# R7FA8M1AH register map
Vendor: Renesas; Series: RA8; File version: 1.2
CPU: CM85 r0p0, little endian, MPU, FPU, VTOR, 4 interrupt priority bits
Registers are 32-bit, read-write, reset 0x0 unless marked. A register's access mark holds for its fields unless they carry their own. Offsets are from the block's base; [hi:lo] are bit positions; {n}, {i} and the like mark numbered series; 'fields as' and 'values as' point back to an identical list.

## DPHYCNT — D-PHY Controller Top
Base 0x40346C00
Same registers: DPHYCNT_NS 0x50346C00
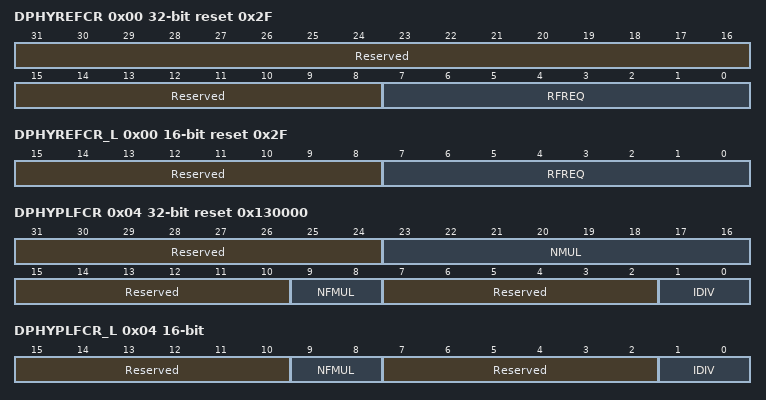
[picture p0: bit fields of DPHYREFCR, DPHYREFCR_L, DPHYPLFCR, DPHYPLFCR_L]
0x00 DPHYREFCR reset 0x2F — D-PHY Reference Clock Setting Register
  [31:8] Reserved — These bits are read as 000000000000000000000000. The write value should be 000000000000000000000000.
  [7:0] RFREQ — Reference Clock Frequency Setting
    39=40MHz; 40=41MHz; 41=42MHz; 117=118MHz; 118=119MHz; 119=120MHz
0x00 DPHYREFCR_L 16-bit reset 0x2F (alternate view of DPHYREFCR) — D-PHY Reference Clock Setting Register
  [15:8] Reserved — These bits are read as 00000000. The write value should be 00000000.
  [7:0] RFREQ — Reference Clock Frequency Setting
    values as DPHYREFCR.RFREQ
0x00 DPHYREFCR_LL 8-bit reset 0x2F (alternate view of DPHYREFCR) — D-PHY Reference Clock Setting Register
  [7:0] RFREQ — Reference Clock Frequency Setting
    values as DPHYREFCR.RFREQ
0x04 DPHYPLFCR reset 0x130000 — D-PHY PLL Frequency Control Register
  [31:24] Reserved — These bits are read as 00000000. The write value should be 00000000.
  [23:16] NMUL — D-PHY PLL Frequency Multiplication Factor Select (Integer Part)
    19=20; 20=21; 21=22; 98=99; 99=100; 100=101
  [15:10] Reserved — These bits are read as 000000. The write value should be 000000.
  [9:8] NFMUL — D-PHY PLL Frequency Multiplication Factor Select (Fractional Part)
    0=0.00; 1=0.33; 2=0.66; 3=0.50
  [7:2] Reserved — These bits are read as 000000. The write value should be 000000.
  [1:0] IDIV — D-PHY PLL Input Frequency Division Ratio Select
    0=1; 1=1/2; 2=1/3; 3=1/4
0x04 DPHYPLFCR_L 16-bit (alternate view of DPHYPLFCR) — D-PHY PLL Frequency Control Register
  [15:10] Reserved — These bits are read as 000000. The write value should be 000000.
  [9:8] NFMUL — D-PHY PLL Frequency Multiplication Factor Select (Fractional Part)
    0=0.00; 1=0.33; 2=0.66; 3=0.50
  [7:2] Reserved — These bits are read as 000000. The write value should be 000000.
  [1:0] IDIV — D-PHY PLL Input Frequency Division Ratio Select
    0=1; 1=1/2; 2=1/3; 3=1/4
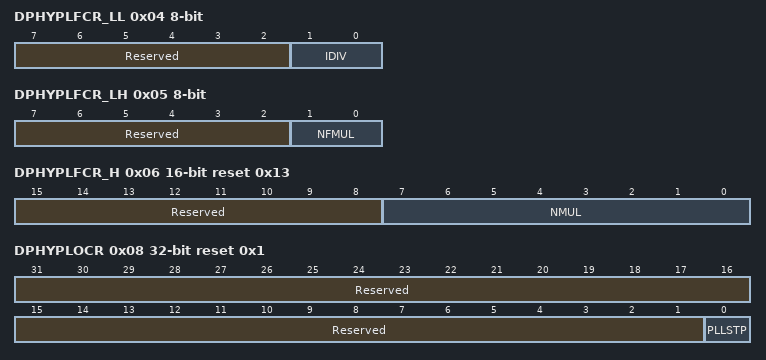
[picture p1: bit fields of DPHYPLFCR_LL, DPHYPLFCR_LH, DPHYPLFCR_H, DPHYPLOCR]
0x04 DPHYPLFCR_LL 8-bit (alternate view of DPHYPLFCR) — D-PHY PLL Frequency Control Register
  [7:2] Reserved — These bits are read as 000000. The write value should be 000000.
  [1:0] IDIV — D-PHY PLL Input Frequency Division Ratio Select
    0=1; 1=1/2; 2=1/3; 3=1/4
0x05 DPHYPLFCR_LH 8-bit (alternate view of DPHYPLFCR) — D-PHY PLL Frequency Control Register
  [7:2] Reserved — These bits are read as 000000. The write value should be 000000.
  [1:0] NFMUL — D-PHY PLL Frequency Multiplication Factor Select (Fractional Part)
    0=0.00; 1=0.33; 2=0.66; 3=0.50
0x06 DPHYPLFCR_H 16-bit reset 0x13 (alternate view of DPHYPLFCR) — D-PHY PLL Frequency Control Register
  [15:8] Reserved — These bits are read as 00000000. The write value should be 00000000.
  [7:0] NMUL — D-PHY PLL Frequency Multiplication Factor Select (Integer Part)
    19=20; 20=21; 21=22; 98=99; 99=100; 100=101
0x06 DPHYPLFCR_HL 8-bit reset 0x13 (alternate view of DPHYPLFCR) — D-PHY PLL Frequency Control Register
  [7:0] NMUL — D-PHY PLL Frequency Multiplication Factor Select (Integer Part)
    19=20; 20=21; 21=22; 98=99; 99=100; 100=101
0x08 DPHYPLOCR reset 0x1 — D-PHY PLL Operation Control Register
  [31:1] Reserved — These bits are read as 0000000000000000000000000000000. The write value should be 0000000000000000000000000000000.
  [0] PLLSTP — D-PHY PLL Operation Control
    0=Operate the PLL; 1=Stop the PLL
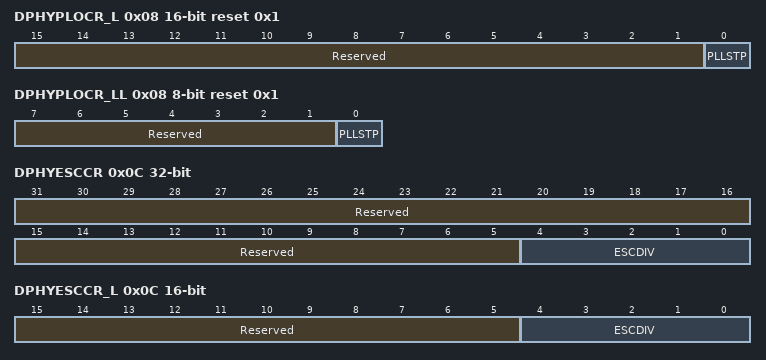
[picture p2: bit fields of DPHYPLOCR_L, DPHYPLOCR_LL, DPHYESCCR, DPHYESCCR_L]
0x08 DPHYPLOCR_L 16-bit reset 0x1 (alternate view of DPHYPLOCR) — D-PHY PLL Operation Control Register
  [15:1] Reserved — These bits are read as 000000000000000. The write value should be 000000000000000.
  [0] PLLSTP — D-PHY PLL Operation Control
    0=Operate the PLL; 1=Stop the PLL
0x08 DPHYPLOCR_LL 8-bit reset 0x1 (alternate view of DPHYPLOCR) — D-PHY PLL Operation Control Register
  [7:1] Reserved — These bits are read as 0000000. The write value should be 0000000.
  [0] PLLSTP — D-PHY PLL Operation Control
    0=Operate the PLL; 1=Stop the PLL
0x0C DPHYESCCR — D-PHY Escape Mode Clock Control Register
  [31:5] Reserved — These bits are read as 000000000000000000000000000. The write value should be 000000000000000000000000000.
  [4:0] ESCDIV — Escape Mode Transfer Clock Division Ratio
    {v}=x1/{v+1} (v=0..3); 29=x1/30; 30=x1/31; 31=x1/32
0x0C DPHYESCCR_L 16-bit (alternate view of DPHYESCCR) — D-PHY Escape Mode Clock Control Register
  [15:5] Reserved — These bits are read as 00000000000. The write value should be 00000000000.
  [4:0] ESCDIV — Escape Mode Transfer Clock Division Ratio
    {v}=x1/{v+1} (v=0..3); 29=x1/30; 30=x1/31; 31=x1/32
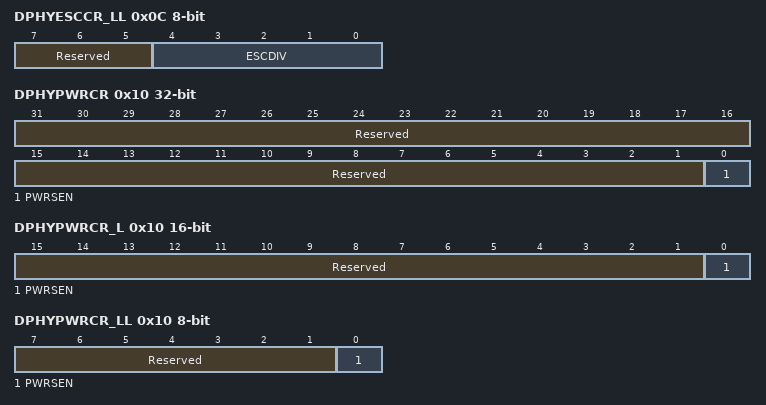
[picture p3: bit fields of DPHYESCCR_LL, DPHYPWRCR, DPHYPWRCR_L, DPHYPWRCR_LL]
0x0C DPHYESCCR_LL 8-bit (alternate view of DPHYESCCR) — D-PHY Escape Mode Clock Control Register
  [7:5] Reserved — These bits are read as 000. The write value should be 000.
  [4:0] ESCDIV — Escape Mode Transfer Clock Division Ratio
    {v}=x1/{v+1} (v=0..3); 29=x1/30; 30=x1/31; 31=x1/32
0x10 DPHYPWRCR — D-PHY Power Supplying Control Register
  [31:1] Reserved — These bits are read as 0000000000000000000000000000000. The write value should be 0000000000000000000000000000000.
  [0] PWRSEN — D-PHY Power Supplying Control
    0=Disable D-PHY LDO operation (Stop supplying VDD_DPHY); 1=Enable D-PHY LDO operation (Supply VDD_DPHY)
0x10 DPHYPWRCR_L 16-bit (alternate view of DPHYPWRCR) — D-PHY Power Supplying Control Register
  [15:1] Reserved — These bits are read as 000000000000000. The write value should be 000000000000000.
  [0] PWRSEN — D-PHY Power Supplying Control
    values as DPHYPWRCR.PWRSEN
0x10 DPHYPWRCR_LL 8-bit (alternate view of DPHYPWRCR) — D-PHY Power Supplying Control Register
  [7:1] Reserved — These bits are read as 0000000. The write value should be 0000000.
  [0] PWRSEN — D-PHY Power Supplying Control
    values as DPHYPWRCR.PWRSEN
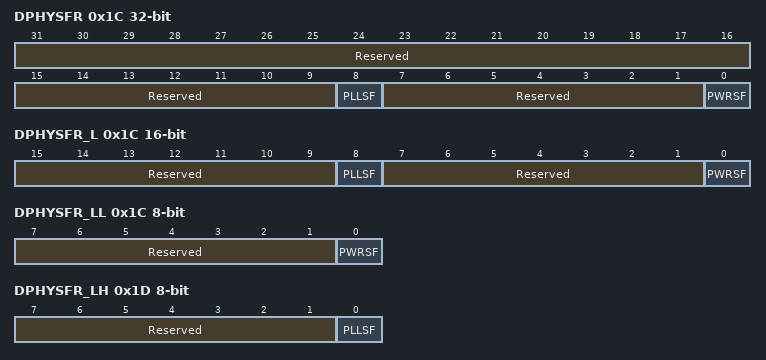
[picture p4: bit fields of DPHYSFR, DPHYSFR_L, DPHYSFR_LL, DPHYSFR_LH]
0x1C DPHYSFR ro — D-PHY Status Flag Register
  [31:9] Reserved — These bits are read as 00000000000000000000000.
  [8] PLLSF — D-PHY PLL Oscillation Stabilization Flag
    0=D-PHY PLL clock is stopped or is not yet stable; 1=D-PHY PLL clock is stable
  [7:1] Reserved — These bits are read as 0000000.
  [0] PWRSF — D-PHY LDO Power-on Status Flag
    0=D-PHY LDO is stopped or starting up; 1=D-PHY LDO startup is completed (VDD_DPHY is stable)
0x1C DPHYSFR_L 16-bit ro (alternate view of DPHYSFR) — D-PHY Status Flag Register
  [15:9] Reserved — These bits are read as 0000000.
  [8] PLLSF — D-PHY PLL Oscillation Stabilization Flag
    values as DPHYSFR.PLLSF
  [7:1] Reserved — These bits are read as 0000000.
  [0] PWRSF — D-PHY LDO Power-on Status Flag
    values as DPHYSFR.PWRSF
0x1C DPHYSFR_LL 8-bit ro (alternate view of DPHYSFR) — D-PHY Status Flag Register
  [7:1] Reserved — These bits are read as 0000000.
  [0] PWRSF — D-PHY LDO Power-on Status Flag
    values as DPHYSFR.PWRSF
0x1D DPHYSFR_LH 8-bit ro (alternate view of DPHYSFR) — D-PHY Status Flag Register
  [7:1] Reserved — These bits are read as 0000000.
  [0] PLLSF — D-PHY PLL Oscillation Stabilization Flag
    values as DPHYSFR.PLLSF
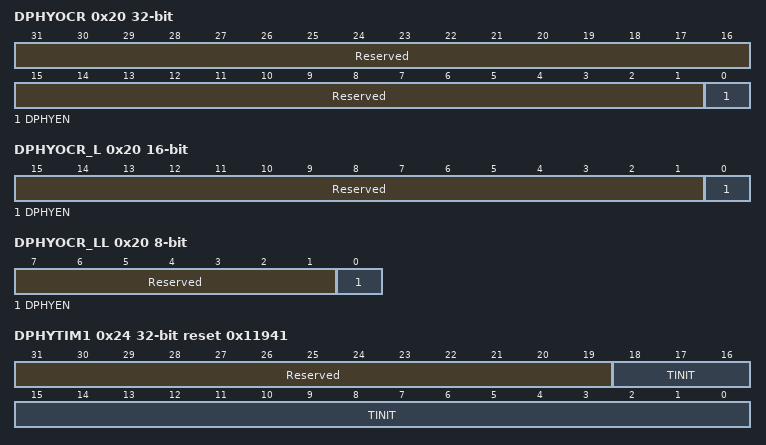
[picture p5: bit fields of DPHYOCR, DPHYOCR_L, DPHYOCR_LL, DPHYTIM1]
0x20 DPHYOCR — D-PHY Operation Control Register
  [31:1] Reserved — These bits are read as 0000000000000000000000000000000. The write value should be 0000000000000000000000000000000.
  [0] DPHYEN — D-PHY Operation Control
    0=Disable D-PHY operation; 1=Enable D-PHY operation
0x20 DPHYOCR_L 16-bit (alternate view of DPHYOCR) — D-PHY Operation Control Register
  [15:1] Reserved — These bits are read as 000000000000000. The write value should be 000000000000000.
  [0] DPHYEN — D-PHY Operation Control
    0=Disable D-PHY operation; 1=Enable D-PHY operation
0x20 DPHYOCR_LL 8-bit (alternate view of DPHYOCR) — D-PHY Operation Control Register
  [7:1] Reserved — These bits are read as 0000000. The write value should be 0000000.
  [0] DPHYEN — D-PHY Operation Control
    0=Disable D-PHY operation; 1=Enable D-PHY operation
0x24 DPHYTIM1 reset 0x11941 — D-PHY Timing Control Register 1
  [31:19] Reserved — These bits are read as 0000000000000. The write value should be 0000000000000.
  [18:0] TINIT — D-PHY T_INIT Parameter Setting
0x24 DPHYTIM1_L 16-bit reset 0x1941 (alternate view of DPHYTIM1) — D-PHY Timing Control Register 1
  [15:0] TINIT — D-PHY T_INIT Parameter Setting
0x24 DPHYTIM1_LL 8-bit reset 0x41 (alternate view of DPHYTIM1) — D-PHY Timing Control Register 1
  [7:0] TINIT — D-PHY T_INIT Parameter Setting
0x25 DPHYTIM1_LH 8-bit reset 0x19 (alternate view of DPHYTIM1) — D-PHY Timing Control Register 1
  [7:0] TINIT — D-PHY T_INIT Parameter Setting
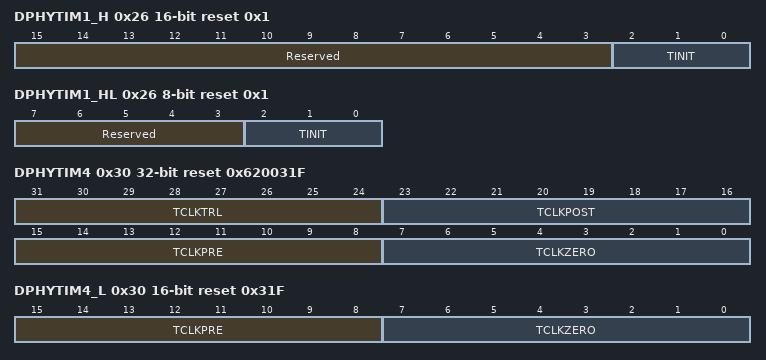
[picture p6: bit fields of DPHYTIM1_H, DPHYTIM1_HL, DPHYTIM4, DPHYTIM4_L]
0x26 DPHYTIM1_H 16-bit reset 0x1 (alternate view of DPHYTIM1) — D-PHY Timing Control Register 1
  [15:3] Reserved — These bits are read as 0000000000000. The write value should be 0000000000000.
  [2:0] TINIT — D-PHY T_INIT Parameter Setting
0x26 DPHYTIM1_HL 8-bit reset 0x1 (alternate view of DPHYTIM1) — D-PHY Timing Control Register 1
  [7:3] Reserved — These bits are read as 00000. The write value should be 00000.
  [2:0] TINIT — D-PHY T_INIT Parameter Setting
0x28 DPHYTIM2_LL 8-bit reset 0x8 (alternate view of DPHYTIM2) — D-PHY Timing Control Register 2
  [7:0] TCLKPREP — D-PHY T_CLK_PREPARE Parameter Setting
0x29 DPHYTIM2_LH 8-bit reset 0x10 (alternate view of DPHYTIM2) — D-PHY Timing Control Register 2
  [7:0] Reserved — These bits are read as 00010000. The write value should be 00010000.
0x2A DPHYTIM2_HL 8-bit reset 0x2 (alternate view of DPHYTIM2) — D-PHY Timing Control Register 2
  [7:0] Reserved — These bits are read as 00000010. The write value should be 00000010.
0x2C DPHYTIM3_LL 8-bit reset 0x8 (alternate view of DPHYTIM3) — D-PHY Timing Control Register 3
  [7:0] THSPREP — D-PHY T_THS_PREPARE Parameter Setting
0x2D DPHYTIM3_LH 8-bit reset 0x10 (alternate view of DPHYTIM3) — D-PHY Timing Control Register 3
  fields as DPHYTIM2_LH
0x30 DPHYTIM4 reset 0x620031F — D-PHY Timing Control Register 4
  [31:24] TCLKTRL — D-PHY T_TCLK_TRAIL Parameter Setting
  [23:16] TCLKPOST — D-PHY T_TCLK_POST Parameter Setting
  [15:8] TCLKPRE — D-PHY T_TCLK_PRE Parameter Setting
  [7:0] TCLKZERO — D-PHY T_CLK_ZERO Parameter Setting
0x30 DPHYTIM4_L 16-bit reset 0x31F (alternate view of DPHYTIM4) — D-PHY Timing Control Register 4
  [15:8] TCLKPRE — D-PHY T_TCLK_PRE Parameter Setting
  [7:0] TCLKZERO — D-PHY T_CLK_ZERO Parameter Setting
0x30 DPHYTIM4_LL 8-bit reset 0x1F (alternate view of DPHYTIM4) — D-PHY Timing Control Register 4
  [7:0] TCLKZERO — D-PHY T_CLK_ZERO Parameter Setting
0x31 DPHYTIM4_LH 8-bit reset 0x3 (alternate view of DPHYTIM4) — D-PHY Timing Control Register 4
  [7:0] TCLKPRE — D-PHY T_TCLK_PRE Parameter Setting
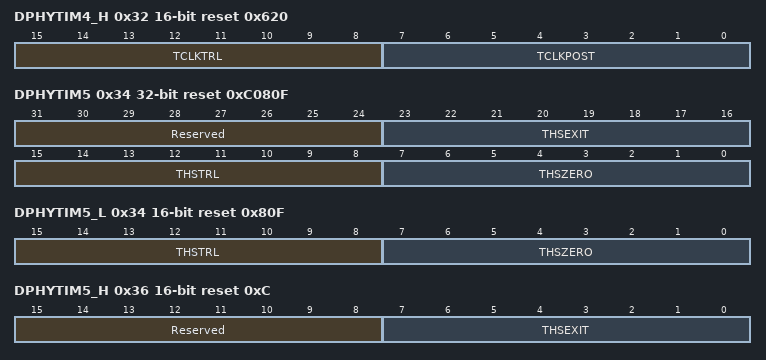
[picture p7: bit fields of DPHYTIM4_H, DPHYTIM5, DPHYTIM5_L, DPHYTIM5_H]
0x32 DPHYTIM4_H 16-bit reset 0x620 (alternate view of DPHYTIM4) — D-PHY Timing Control Register 4
  [15:8] TCLKTRL — D-PHY T_TCLK_TRAIL Parameter Setting
  [7:0] TCLKPOST — D-PHY T_TCLK_POST Parameter Setting
0x32 DPHYTIM4_HL 8-bit reset 0x20 (alternate view of DPHYTIM4) — D-PHY Timing Control Register 4
  [7:0] TCLKPOST — D-PHY T_TCLK_POST Parameter Setting
0x33 DPHYTIM4_HH 8-bit reset 0x6 (alternate view of DPHYTIM4) — D-PHY Timing Control Register 4
  [7:0] TCLKTRL — D-PHY T_TCLK_TRAIL Parameter Setting
0x34 DPHYTIM5 reset 0xC080F — D-PHY Timing Control Register 5
  [31:24] Reserved — These bits are read as 00000000. The write value should be 00000000.
  [23:16] THSEXIT — D-PHY T_THS_EXIT Parameter Setting
  [15:8] THSTRL — D-PHY T_THS_TRAIL Parameter Setting
  [7:0] THSZERO — D-PHY T_THS_ZERO Parameter Setting
0x34 DPHYTIM5_L 16-bit reset 0x80F (alternate view of DPHYTIM5) — D-PHY Timing Control Register 5
  [15:8] THSTRL — D-PHY T_THS_TRAIL Parameter Setting
  [7:0] THSZERO — D-PHY T_THS_ZERO Parameter Setting
0x34 DPHYTIM5_LL 8-bit reset 0xF (alternate view of DPHYTIM5) — D-PHY Timing Control Register 5
  [7:0] THSZERO — D-PHY T_THS_ZERO Parameter Setting
0x35 DPHYTIM5_LH 8-bit reset 0x8 (alternate view of DPHYTIM5) — D-PHY Timing Control Register 5
  [7:0] THSTRL — D-PHY T_THS_TRAIL Parameter Setting
0x36 DPHYTIM5_H 16-bit reset 0xC (alternate view of DPHYTIM5) — D-PHY Timing Control Register 5
  [15:8] Reserved — These bits are read as 00000000. The write value should be 00000000.
  [7:0] THSEXIT — D-PHY T_THS_EXIT Parameter Setting
0x36 DPHYTIM5_HL 8-bit reset 0xC (alternate view of DPHYTIM5) — D-PHY Timing Control Register 5
  [7:0] THSEXIT — D-PHY T_THS_EXIT Parameter Setting
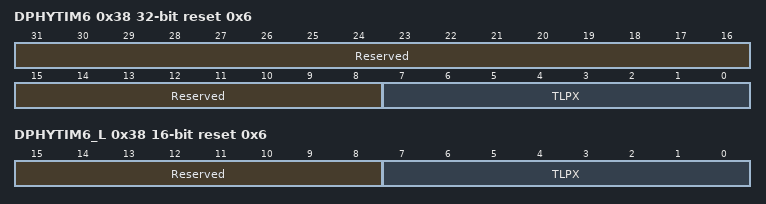
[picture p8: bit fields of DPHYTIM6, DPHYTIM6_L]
0x38 DPHYTIM6 reset 0x6 — D-PHY Timing Control Register 6
  [31:8] Reserved — These bits are read as 000000000000000000000000. The write value should be 000000000000000000000000.
  [7:0] TLPX — D-PHY T_TLPX Parameter Setting
0x38 DPHYTIM6_L 16-bit reset 0x6 (alternate view of DPHYTIM6) — D-PHY Timing Control Register 6
  [15:8] Reserved — These bits are read as 00000000. The write value should be 00000000.
  [7:0] TLPX — D-PHY T_TLPX Parameter Setting
0x38 DPHYTIM6_LL 8-bit reset 0x6 (alternate view of DPHYTIM6) — D-PHY Timing Control Register 6
  [7:0] TLPX — D-PHY T_TLPX Parameter Setting
